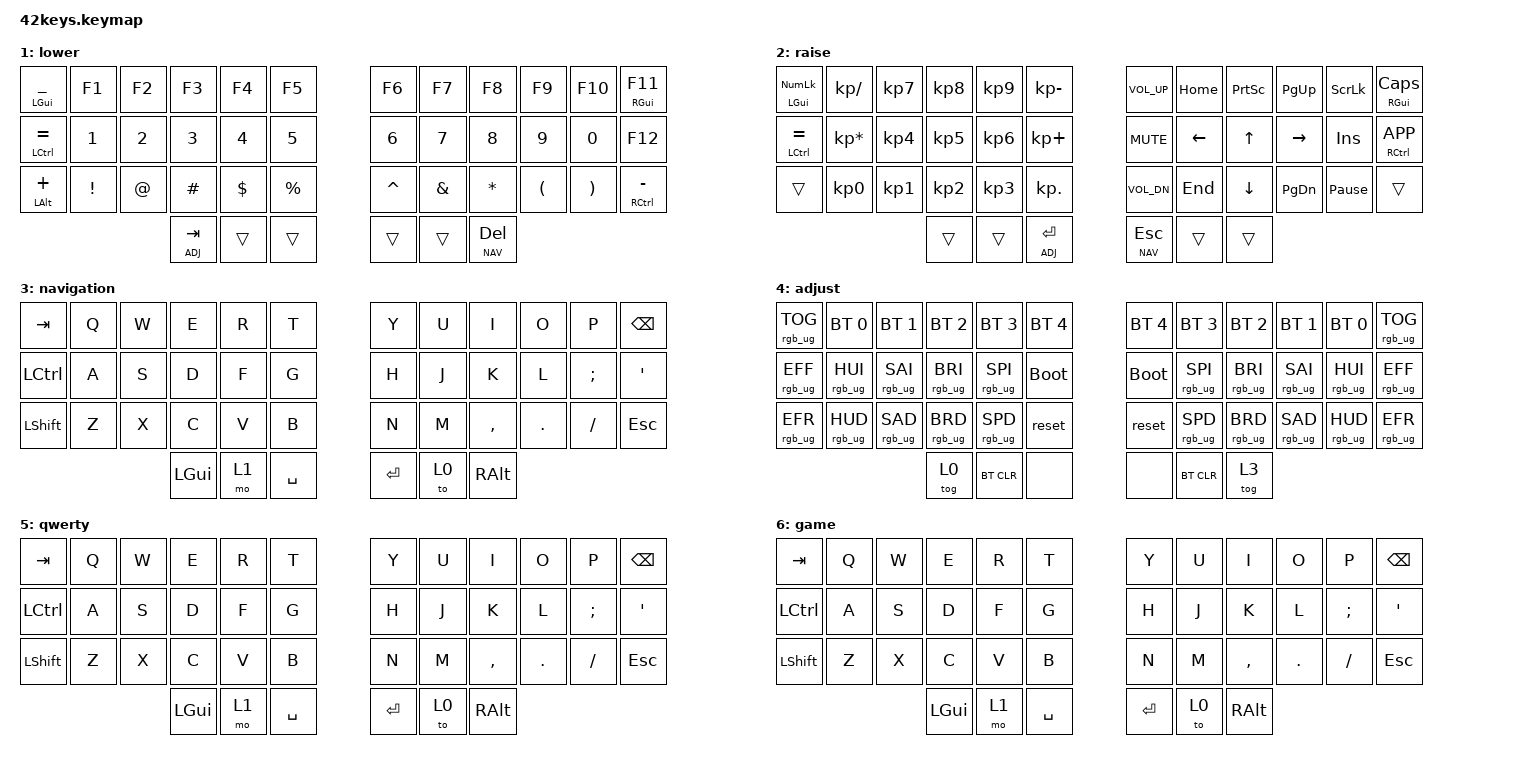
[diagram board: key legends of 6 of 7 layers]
#include <behaviors.dtsi>
#include <dt-bindings/zmk/keys.h>
#include <dt-bindings/zmk/bt.h>
// #include <dt-bindings/zmk/mouse.h>
#include <dt-bindings/zmk/outputs.h>
#include <dt-bindings/zmk/rgb.h> // Enable Only with huge battery 850 mAh + (original setup: 110 mAh)
#include <dt-bindings/zmk/ext_power.h>
#include "42keys.h"

/ {

        keymap {
                compatible = "zmk,keymap";

                default_layer {
// -----------------------------------------------------------------------------------------
// |  TAB |  Y  |  C  |  L  |  M  |  K  |   |  Z  |  F   |  U  |  ,  |  '  | BKSP |
// | CTRL |  I  |  S  |  R  |  T  |  G  |   |  P  |  N   |  E  |  A  |  O  |  ;   |
// | SHFT |  Q  |  V  |  W  |  D  |  J  |   |  B  |  H   |  /  |  .  |  X  | ESC  |
//                    | GUI | LWR | SPC |   | ENT | RSE  | ALT |
                        label = "default";
                        bindings = <
   &rgb_ug RGB_TOG  &bt BT_SEL 0    &bt BT_SEL 1    &bt BT_SEL 2    &bt BT_SEL 3 &bt BT_SEL 4   &none &none &none &none &ext_power EP_TOG &ext_power EP_ON &rgb_ug RGB_TOG
   &rgb_ug RGB_EFF  &rgb_ug RGB_HUI &rgb_ug RGB_SAI &rgb_ug RGB_BRI &rgb_ug RGB_SPI        &none &none &none &none &none &none &none
   &rgb_ug RGB_EFR  &rgb_ug RGB_HUD &rgb_ug RGB_SAD &rgb_ug RGB_BRD &rgb_ug RGB_SPD        &none &none &none &none &none &none &none
                                                                 &tog 0 &bt BT_CLR &none         &none &none &none
                        >;
                };

                lower_layer {
// -----------------------------------------------------------------------------------------
// |  _  |  F1 |  F2 |  F3 |  F4 |  F5 |    |  F6 |  F7 |  F8 |  F9 | F10 | F11 | 
// |  =  |  1  |  2  |  3  |  4  |  5  |    |  6  |  7  |  8  |  9  |  0  | F12 |
// |  +  |  !  |  @  |  #  |  $  |  %  |    |  ^  |  &  |  *  |  (  |  )  |  -  |
//                   | ADJ |     |     |    |     |     | NAV |
                        label = "lower";
                        bindings = <
   &mt LGUI UNDER  &kp F1   &kp F2 &kp F3      &kp F4   &kp F5		&kp F6    &kp F7   &kp F8   &kp F9   &kp F10  &mt RGUI F11
   &mt LCTRL EQUAL &kp N1   &kp N2 &kp N3      &kp N4   &kp N5		&kp N6    &kp N7   &kp N8   &kp N9   &kp N0   &kp F12
   &mt LALT PLUS   &kp EXCL &kp AT &kp HASH    &kp DLLR &kp PRCNT	&kp CARET &kp AMPS &kp STAR &kp LPAR &kp RPAR &mt RCTRL MINUS
                                   &lt ADJ TAB &trans   &trans		&trans    &trans   &lt NAV DEL
                        >;
                };

                raise_layer {
// -----------------------------------------------------------------------------------------
// | NMLK |  /  |  7  |  8  |  9  |  -  |   | VOLU| HOME| PRSC| PGUP| SCLK| CLCK|     
// | CTRL |  *  |  4  |  5  |  6  |  +  |   | MUT | LEFT|  UP | RGHT| INS | APP |
// |      |  0  |  1  |  2  |  3  |  .  |   | VOLD| END | DOWN| PGDN| PAUS|     |
//                    |     |     | ADJ |   | NAV |     |     |
                        label = "raise";
                        bindings = <
   &mt LGUI KP_NUM &kp KP_SLASH    &kp KP_N7 &kp KP_N8 &kp KP_N9 &kp KP_MINUS        	&kp C_VOL_UP &kp HOME &kp PSCRN &kp PG_UP &kp SLCK &mt RGUI CAPS
   &mt LCTRL EQUAL &kp KP_MULTIPLY &kp KP_N4 &kp KP_N5 &kp KP_N6 &kp KP_PLUS         	&kp C_MUTE   &kp LEFT &kp UP    &kp RIGHT &kp INS  &mt RCTRL K_APP
   &trans          &kp KP_N0       &kp KP_N1 &kp KP_N2 &kp KP_N3 &kp KP_DOT          	&kp C_VOL_DN &kp END  &kp DOWN  &kp PG_DN &kp PAUSE_BREAK &trans
                                             &trans &trans &lt ADJ RET 			&lt NAV ESC &trans &trans
                        >;
                };
		navigation_layer {
// -----------------------------------------------------------------------------------------
// |  TAB |  FQIT | SLF |  ˄   | SDW |  Q,H  |   | LCK | PTAB| NTAB| FWRD|     | BKSP |
// | CTRL |  SWAP |  ˂  | OTOG |  ˃  |CMD,DEL|   | LEFT| DOWN| UP  |RIGHT| RCK | CAPS |
// | SHFT |  OPTS | SRG |  ˅   | SUP |       |   | HOME| PUP | PDW | END | RSHT| ESC  |
//                      | GUI  | TL0 | SPC   |   | ENT | TG4 | ALT |
                        label = "navigation";
			bindings = <
   &kp TAB   &kp Q &kp W &kp E &kp R &kp T   &kp Y &kp U  &kp I     &kp O   &kp P    &kp BSPC
   &kp LCTRL &kp A &kp S &kp D &kp F &kp G   &kp H &kp J  &kp K     &kp L   &kp SEMI &kp SQT
   &kp LSHFT &kp Z &kp X &kp C &kp V &kp B   &kp N &kp M  &kp COMMA &kp DOT &kp FSLH &kp ESC
                  &kp LGUI &mo 1 &kp SPACE   &kp RET &to 0 &kp RALT
			>;
		};
                adjsut_layer {
// -----------------------------------------------------------------------------------------------
// | RGBTOG| BT0 | BT1 | BT2 | BT3  | BT4 |   | BT4 | BT3  | BT2 | BT1 | BT0 | RGBTOG|
// | MOD+  | HUE+| SAT+| VAL+| SPD+ | BLDR|   | BLDR| SPD+ | VAL+| SAT+| HUE+| MOD+  |
// | MOD-  | HUE-| SAT-| VAL-| SPD- | RST |   | RST | SPD- | VAL-| SAT-| HUE-| MOD-  |
//                     |     | BTCLR| EXPW|   | EXPW| BTCLR| TG3 |
                        label = "adjust";
                        bindings = <
   &rgb_ug RGB_TOG  &bt BT_SEL 0    &bt BT_SEL 1    &bt BT_SEL 2    &bt BT_SEL 3 &bt BT_SEL 4   &bt BT_SEL 4 &bt BT_SEL 3 &bt BT_SEL 2    &bt BT_SEL 1    &bt BT_SEL 0    &rgb_ug RGB_TOG
   &rgb_ug RGB_EFF  &rgb_ug RGB_HUI &rgb_ug RGB_SAI &rgb_ug RGB_BRI &rgb_ug RGB_SPI        &bootloader    &bootloader  &rgb_ug RGB_SPI        &rgb_ug RGB_BRI &rgb_ug RGB_SAI &rgb_ug RGB_HUI &rgb_ug RGB_EFF
   &rgb_ug RGB_EFR  &rgb_ug RGB_HUD &rgb_ug RGB_SAD &rgb_ug RGB_BRD &rgb_ug RGB_SPD        &reset         &reset       &rgb_ug RGB_SPD        &rgb_ug RGB_BRD &rgb_ug RGB_SAD &rgb_ug RGB_HUD &rgb_ug RGB_EFR
                                                                 &tog 0 &bt BT_CLR &none         &none &bt BT_CLR &tog 3
                        >;
                };

                qwerty_layer {
// -----------------------------------------------------------------------------------------
// |  TAB |  Q  |  W  |  E  |  R  |  T  |   |  Y  |  U   |  I  |  O  |  P  | BKSP |
// | CTRL |  A  |  S  |  D  |  F  |  G  |   |  H  |  J   |  K  |  L  |  ;  |  '   |
// | SHFT |  Z  |  X  |  C  |  V  |  B  |   |  N  |  M   |  ,  |  .  |  /  | ESC  |
//                    | GUI | LWR | SPC |   | ENT | TO0  | ALT |
                        label = "qwerty";
                        bindings = <
   &kp TAB   &kp Q &kp W &kp E &kp R &kp T   &kp Y &kp U  &kp I     &kp O   &kp P    &kp BSPC
   &kp LCTRL &kp A &kp S &kp D &kp F &kp G   &kp H &kp J  &kp K     &kp L   &kp SEMI &kp SQT
   &kp LSHFT &kp Z &kp X &kp C &kp V &kp B   &kp N &kp M  &kp COMMA &kp DOT &kp FSLH &kp ESC
                  &kp LGUI &mo 1 &kp SPACE   &kp RET &to 0 &kp RALT
                        >;
                };
                game_layer {
// -----------------------------------------------------------------------------------------
// |  TAB |  Q  |  W  |  E  |  R  |  T  |   |  Y  |  U   |  I  |  O  |  P  | BKSP |
// | CTRL |  A  |  S  |  D  |  F  |  G  |   |  H  |  J   |  K  |  L  |  ;  |  '   |
// | SHFT |  Z  |  X  |  C  |  V  |  B  |   |  N  |  M   |  ,  |  .  |  /  | ESC  |
//                    | GUI | LWR | SPC |   | ENT | TO0  | ALT |
                        label = "game";
                        bindings = <
   &kp TAB   &kp Q &kp W &kp E &kp R &kp T   &kp Y &kp U  &kp I     &kp O   &kp P    &kp BSPC
   &kp LCTRL &kp A &kp S &kp D &kp F &kp G   &kp H &kp J  &kp K     &kp L   &kp SEMI &kp SQT
   &kp LSHFT &kp Z &kp X &kp C &kp V &kp B   &kp N &kp M  &kp COMMA &kp DOT &kp FSLH &kp ESC
                  &kp LGUI &mo 1 &kp SPACE   &kp RET &to 0 &kp RALT
                        >;
                };
        };
};
